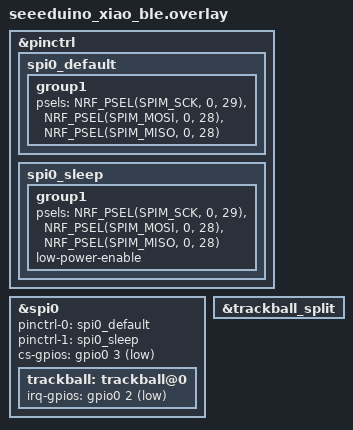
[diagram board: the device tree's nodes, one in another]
&pinctrl {
    spi0_default: spi0_default {
        group1 {
            psels = <NRF_PSEL(SPIM_SCK, 0, 29)>,
                    <NRF_PSEL(SPIM_MOSI, 0, 28)>,
                    <NRF_PSEL(SPIM_MISO, 0, 28)>;
        };
    };

    spi0_sleep: spi0_sleep {
        group1 {
            psels = <NRF_PSEL(SPIM_SCK, 0, 29)>,
                    <NRF_PSEL(SPIM_MOSI, 0, 28)>,
                    <NRF_PSEL(SPIM_MISO, 0, 28)>;
            low-power-enable;
        };
    };
};

&spi0 {
    pinctrl-0 = <&spi0_default>;
    pinctrl-1 = <&spi0_sleep>;
    pinctrl-names = "default", "sleep";
    cs-gpios = <&gpio0 3 GPIO_ACTIVE_LOW>;

    trackball: trackball@0 {
        irq-gpios = <&gpio0 2 (GPIO_ACTIVE_LOW | GPIO_PULL_UP)>;
    };
};

&trackball_split {
    status = "okay";
};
